VERSION ""

NS_ :

BS_:

BU_: EC AC
VAL_TABLE_ MyCanEnum 7 "NA" 6 "ERR" 5 "Description for the value '0x5'" 4 "Description for the value '0x4'" 3 "Description for the value '0x3'" 2 "Description for the value '0x2'" 1 "Value1" 0 "Value0" ;

BO_ 19 MyMessage: 8 Vector__XXX
 SG_ MySignal : 0|3@1+ (1,0) [0|7] "" Vector__XXX

BO_ 2147483652 EC_Status_3: 8 EC
 SG_ EC3_Temp_Floadback : 11|1@0+ (1,0) [0|1] ""  AC
 SG_ EC3_Over_Speed_Fault : 43|1@0+ (1,0) [0|1] ""  AC
 SG_ EC3_Micro_Electronic_Fault : 42|1@0+ (1,0) [0|1] ""  AC
 SG_ EC3_Lost_Phase_Fault : 21|1@0+ (1,0) [0|1] ""  AC
 SG_ EC3_Inverter_Temperature_Open : 61|1@0+ (1,0) [0|1] ""  AC
 SG_ EC3_Inverter_Over_Temp_Fault : 19|1@0+ (1,0) [0|1] ""  AC
 SG_ EC3_Inverter_Over_Current_Fault : 24|1@0+ (1,0) [0|0] ""  AC
 SG_ EC3_Inverter_Current_Imbalance : 40|1@0+ (1,0) [0|1] ""  AC
 SG_ EC3_IGBT_High_Temperature : 3|1@0+ (1,0) [0|1] ""  AC
 SG_ EC3_Fault_Limit_Lockout : 55|1@0+ (1,0) [0|1] ""  AC
 SG_ EC3_DSP_High_Temperature : 2|1@0+ (1,0) [0|1] ""  AC
 SG_ EC3_DC_Voltage_Low : 8|1@0+ (1,0) [0|1] ""  AC
 SG_ EC3_DC_Under_Voltage : 27|1@0+ (1,0) [0|1] ""  AC
 SG_ EC3_DC_Over_Voltage : 26|1@0+ (1,0) [0|1] ""  AC
 SG_ EC3_Current_Flodback : 10|1@0+ (1,0) [0|1] ""  AC
 SG_ EC3_CAN_Communication_lost : 15|1@0+ (1,0) [0|1] ""  AC
 SG_ EC3_Bus_Off_Fault : 0|1@0+ (1,0) [0|1] ""  AC

BO_ 2147483651 EC_Status_2: 8 EC
 SG_ EC2_Phase_Current : 23|16@0+ (0.00390625,0) [0|255.99609375] "A"  AC
 SG_ EC2_DC_Current : 7|16@0+ (0.125,0) [0|65535] "A" Vector__XXX

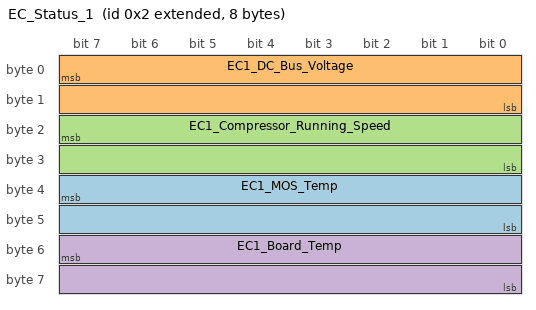
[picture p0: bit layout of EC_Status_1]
BO_ 2147483650 EC_Status_1: 8 EC
 SG_ EC1_MOS_Temp : 39|16@0+ (0.03125,0) [0|2047.96875] "C"  AC
 SG_ EC1_DC_Bus_Voltage : 7|16@0+ (0.0625,0) [0|65535] "V"  AC
 SG_ EC1_Compressor_Running_Speed : 23|16@0+ (0.5,0) [0|65535] "rpm"  AC
 SG_ EC1_Board_Temp : 55|16@0+ (0.03125,0) [0|2047.96875] "C"  AC

BO_ 2147483665 AC_Message: 8 AC
 SG_ AC_Set_Speed : 23|16@0+ (1,0) [0|65535] "rpm"  EC
 SG_ AC_Enable_Disable_Compressor : 7|16@0+ (1,0) [0|1] ""  EC

CM_ SG_ 2147483652 EC3_Temp_Floadback "Not enabled";
CM_ SG_ 2147483652 EC3_Over_Speed_Fault "Motor control Over Speed protection";
CM_ SG_ 2147483652 EC3_Micro_Electronic_Fault "Microelectronics failure  ";
CM_ SG_ 2147483652 EC3_Lost_Phase_Fault "Lost Phase protection";
CM_ SG_ 2147483652 EC3_Inverter_Temperature_Open "Open circuit protection of temperature detection sensor";
CM_ SG_ 2147483652 EC3_Inverter_Over_Temp_Fault "High temperature protection of power devices";
CM_ SG_ 2147483652 EC3_Inverter_Over_Current_Fault "Output overcurrent protection";
CM_ SG_ 2147483652 EC3_Inverter_Current_Imbalance "Output current three-phase imbalance protection";
CM_ SG_ 2147483652 EC3_IGBT_High_Temperature "Power device overtemperature protection";
CM_ SG_ 2147483652 EC3_Fault_Limit_Lockout "Fault override self-locking protection";
CM_ SG_ 2147483652 EC3_DSP_High_Temperature "DSP overtemperature protection";
CM_ SG_ 2147483652 EC3_DC_Voltage_Low "DC undervoltage protection";
CM_ SG_ 2147483652 EC3_DC_Under_Voltage "Low voltage protection of DC voltage";
CM_ SG_ 2147483652 EC3_DC_Over_Voltage "DC voltage overvoltage protection";
CM_ SG_ 2147483652 EC3_Current_Flodback "Output current hysteresis protection";
CM_ SG_ 2147483652 EC3_CAN_Communication_lost "CAN communication signal loss protection";
CM_ SG_ 2147483652 EC3_Bus_Off_Fault "CAN communication bus busoff fault  protection";
CM_ SG_ 2147483651 EC2_Phase_Current "Phase Current feedback from compressor  data/256 ";
CM_ SG_ 2147483651 EC2_DC_Current "DC Current feedback from compressor  data/8";
CM_ SG_ 2147483650 EC1_MOS_Temp "Temperature sensor measured value data/256";
CM_ SG_ 2147483650 EC1_DC_Bus_Voltage "DC Voltage sensor measured value  data/16";
CM_ SG_ 2147483650 EC1_Compressor_Running_Speed "Actual speed feedback from compressor";
CM_ SG_ 2147483650 EC1_Board_Temp "Temperature sensor measured value data/256
";
CM_ SG_ 2147483665 AC_Set_Speed "Target speed";
CM_ SG_ 2147483665 AC_Enable_Disable_Compressor "1=on 0=off
";
BA_DEF_ BO_  "GenMsgCycleTime" INT 0 1000;
BA_DEF_ BO_  "GenMsgSendType" ENUM  "cyclic","vector_leerstring";
BA_DEF_  "BusType" STRING ;
BA_DEF_DEF_  "GenMsgCycleTime" 100;
BA_DEF_DEF_  "GenMsgSendType" "cyclic";
BA_DEF_DEF_  "BusType" "CAN";
VAL_ 19 MySignal 7 "NA" 6 "ERR" 5 "Description for the value '0x5'" 4 "Description for the value '0x4'" 3 "Description for the value '0x3'" 2 "Description for the value '0x2'" 1 "Value1" 0 "Value0" ;
